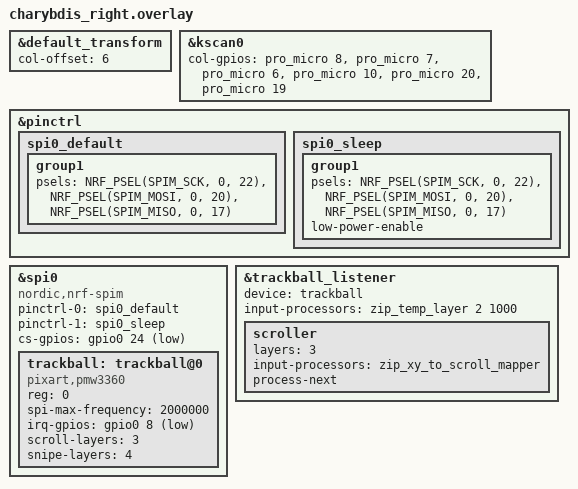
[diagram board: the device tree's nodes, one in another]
#include "charybdis.dtsi"

&default_transform {
	col-offset = <6>;
};

&kscan0 {
	col-gpios
		= <&pro_micro 8 (GPIO_ACTIVE_HIGH | GPIO_PULL_DOWN)>
		, <&pro_micro 7 (GPIO_ACTIVE_HIGH | GPIO_PULL_DOWN)>
		, <&pro_micro 6 (GPIO_ACTIVE_HIGH | GPIO_PULL_DOWN)>
		, <&pro_micro 10 (GPIO_ACTIVE_HIGH | GPIO_PULL_DOWN)>
		, <&pro_micro 20 (GPIO_ACTIVE_HIGH | GPIO_PULL_DOWN)>
		, <&pro_micro 19 (GPIO_ACTIVE_HIGH | GPIO_PULL_DOWN)>
  ;
};

&pinctrl {
    spi0_default: spi0_default {
        group1 {
            psels = <NRF_PSEL(SPIM_SCK, 0, 22)>,
                <NRF_PSEL(SPIM_MOSI, 0, 20)>,
                <NRF_PSEL(SPIM_MISO, 0, 17)>;
        };
    };

    spi0_sleep: spi0_sleep {
        group1 {
            psels = <NRF_PSEL(SPIM_SCK, 0, 22)>,
                <NRF_PSEL(SPIM_MOSI, 0, 20)>,
                <NRF_PSEL(SPIM_MISO, 0, 17)>;
            low-power-enable;
        };
    };
};

&spi0 {
    status = "okay";
    compatible = "nordic,nrf-spim";
    pinctrl-0 = <&spi0_default>;
    pinctrl-1 = <&spi0_sleep>;
    pinctrl-names = "default", "sleep";
    cs-gpios = <&gpio0 24 GPIO_ACTIVE_LOW>;

    trackball: trackball@0 {
        status = "okay";
        compatible = "pixart,pmw3360";
        reg = <0>;
        spi-max-frequency = <2000000>;
        irq-gpios = <&gpio0 8 (GPIO_ACTIVE_LOW | GPIO_PULL_UP)>;
        /* optional features */
        scroll-layers = <3>;
        snipe-layers = <4>;
    };
};

/* Important/Required block */
&trackball_listener {
    status = "okay";
    device = <&trackball>;
    /* Automouse layer provided by the [Temporary Layer Input Processor](https://zmk.dev/docs/keymaps/input-processors/temp-layer#pre-defined-instances) in my case layer 2 with timeout 1000ms */
    input-processors = <&zip_temp_layer 2 1000>;

    /* Scrolling layer provided by the [Code Mapper Input Processor](https://zmk.dev/docs/keymaps/input-processors/code-mapper#pre-defined-instances) in my case layer 3 */
    scroller {
        layers = <3>;
        input-processors = <&zip_xy_to_scroll_mapper>;
        process-next;
    };
};
